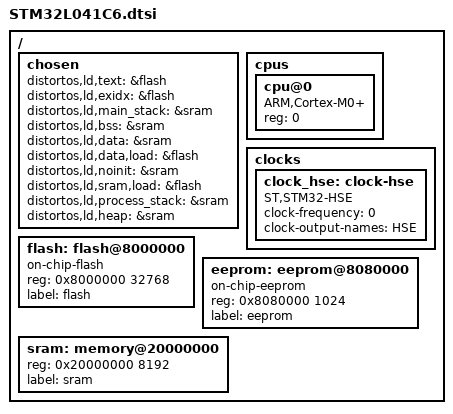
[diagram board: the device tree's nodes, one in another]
/**
 * \file
 * \brief Devicetree fragment for STM32L041C6
 *
 * \author Copyright (C) 2014-2017 Kamil Szczygiel http://www.distortec.com http://www.freddiechopin.info
 *
 * \par License
 * This Source Code Form is subject to the terms of the Mozilla Public License, v. 2.0. If a copy of the MPL was not
 * distributed with this file, You can obtain one at http://mozilla.org/MPL/2.0/.
 *
 * \warning
 * Automatically generated file - do not edit!
 */

#include "ARMv6-M.dtsi"

/ {
	chosen {
		distortos,ld,text = &flash;
		distortos,ld,exidx = &flash;
		distortos,ld,main_stack = &sram;
		distortos,ld,bss = &sram;
		distortos,ld,data = &sram;
		distortos,ld,data,load = &flash;
		distortos,ld,noinit = &sram;
		distortos,ld,sram,load = &flash;
		distortos,ld,process_stack = &sram;
		distortos,ld,heap = &sram;
	};

	cpus {
		#address-cells = <1>;
		#size-cells = <0>;

		cpu@0 {
			compatible = "ARM,Cortex-M0+", "ARM,ARMv6-M";
			device_type = "cpu";
			reg = <0>;
		};
	};

	clocks {
		clock_hse: clock-hse {
			#clock-cells = <0>;
			compatible = "ST,STM32-HSE", "fixed-clock";
			clock-frequency = <0>;
			clock-output-names = "HSE";
		};
	};

	flash: flash@8000000 {
		compatible = "on-chip-flash";
		reg = <0x8000000 32768>;
		label = "flash";
	};

	eeprom: eeprom@8080000 {
		compatible = "on-chip-eeprom";
		reg = <0x8080000 1024>;
		label = "eeprom";
	};

	sram: memory@20000000 {
		device_type = "memory";
		reg = <0x20000000 8192>;
		label = "sram";
	};
};
